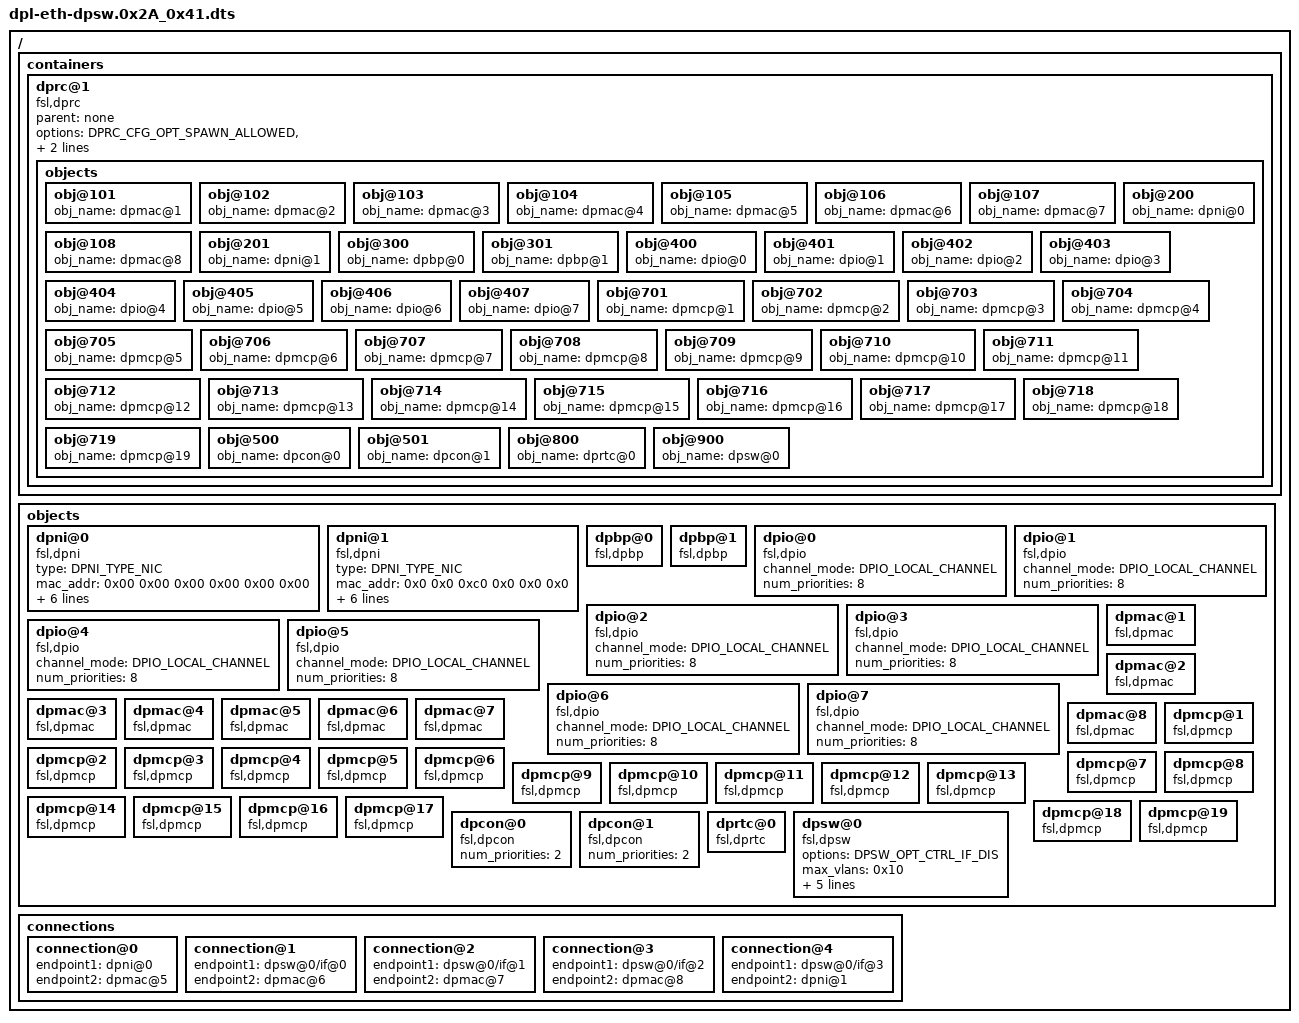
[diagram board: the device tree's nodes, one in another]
/*
 * Copyright 2014-2016 Freescale Semiconductor, Inc.
 * Copyright 2017 NXP
 *
 * Redistribution and use in source and binary forms, with or without
 * modification, are permitted provided that the following conditions are met:
 *   * Redistributions of source code must retain the above copyright
 *     notice, this list of conditions and the following disclaimer.
 *   * Redistributions in binary form must reproduce the above copyright
 *     notice, this list of conditions and the following disclaimer in the
 *     documentation and/or other materials provided with the distribution.
 *   * Neither the name of the above-listed copyright holders nor the
 *     names of any contributors may be used to endorse or promote products
 *     derived from this software without specific prior written permission.
 *
 * THIS SOFTWARE IS PROVIDED BY THE COPYRIGHT HOLDERS AND CONTRIBUTORS "AS IS"
 * AND ANY EXPRESS OR IMPLIED WARRANTIES, INCLUDING, BUT NOT LIMITED TO, THE
 * IMPLIED WARRANTIES OF MERCHANTABILITY AND FITNESS FOR A PARTICULAR PURPOSE
 * ARE DISCLAIMED. IN NO EVENT SHALL THE COPYRIGHT HOLDERS OR CONTRIBUTORS BE
 * LIABLE FOR ANY DIRECT, INDIRECT, INCIDENTAL, SPECIAL, EXEMPLARY, OR
 * CONSEQUENTIAL DAMAGES (INCLUDING, BUT NOT LIMITED TO, PROCUREMENT OF
 * SUBSTITUTE GOODS OR SERVICES; LOSS OF USE, DATA, OR PROFITS; OR BUSINESS
 * INTERRUPTION) HOWEVER CAUSED AND ON ANY THEORY OF LIABILITY, WHETHER IN
 * CONTRACT, STRICT LIABILITY, OR TORT (INCLUDING NEGLIGENCE OR OTHERWISE)
 * ARISING IN ANY WAY OUT OF THE USE OF THIS SOFTWARE, EVEN IF ADVISED OF THE
 * POSSIBILITY OF SUCH DAMAGE.
 */

/*
 * "Bootstrap DPL" for ls2088a RDB boards featuring SerDes 0x2A_0x41.
 * This DPL defines one network interface mapped on the ETH0 copper port and an
 * L2 switch, ports connected to internal interface ni1 and copper ports ETH1, ETH2
 * and ETH3.
 */
/dts-v1/;
/ {
	/*****************************************************************
         * Containers
         *****************************************************************/
	containers {
		dprc@1 {
			compatible = "fsl,dprc";
			parent = "none";
			options = "DPRC_CFG_OPT_SPAWN_ALLOWED" , "DPRC_CFG_OPT_ALLOC_ALLOWED", "DPRC_CFG_OPT_IRQ_CFG_ALLOWED";
			objects {
				/* ------------- MACs --------------*/
				obj@101 {
					obj_name = "dpmac@1";
				};
				obj@102 {
					obj_name = "dpmac@2";
				};
				obj@103 {
					obj_name = "dpmac@3";
				};
				obj@104 {
					obj_name = "dpmac@4";
				};
				obj@105 {
					obj_name = "dpmac@5";
				};
				obj@106 {
					obj_name = "dpmac@6";
				};
				obj@107 {
					obj_name = "dpmac@7";
				};
				obj@108 {
					obj_name = "dpmac@8";
				};

				/* ------------ DPNIs --------------*/
				obj@200 {
					obj_name = "dpni@0";
				};
				obj@201 {
					obj_name = "dpni@1";
				};

				/* ------------ DPBPs --------------*/
				obj@300 {
					obj_name = "dpbp@0";
				};
				obj@301 {
					obj_name = "dpbp@1";
				};

				/* ------------ DPIOs --------------*/
				obj@400 {
					obj_name = "dpio@0";
				};
				obj@401 {
					obj_name = "dpio@1";
				};
				obj@402 {
					obj_name = "dpio@2";
				};
				obj@403 {
					obj_name = "dpio@3";
				};
				obj@404 {
					obj_name = "dpio@4";
				};
				obj@405 {
					obj_name = "dpio@5";
				};
				obj@406 {
					obj_name = "dpio@6";
				};
				obj@407 {
					obj_name = "dpio@7";
				};

				/* ------------ DPMCPs --------------*/
				obj@701 {
					obj_name = "dpmcp@1";
				};
				obj@702 {
					obj_name = "dpmcp@2";
				};
				obj@703 {
					obj_name = "dpmcp@3";
				};
				obj@704 {
					obj_name = "dpmcp@4";
				};
				obj@705 {
					obj_name = "dpmcp@5";
				};
				obj@706 {
					obj_name = "dpmcp@6";
				};
				obj@707 {
					obj_name = "dpmcp@7";
				};
				obj@708 {
					obj_name = "dpmcp@8";
				};
				obj@709 {
					obj_name = "dpmcp@9";
				};
				obj@710 {
					obj_name = "dpmcp@10";
				};
				obj@711 {
					obj_name = "dpmcp@11";
				};
				obj@712 {
					obj_name = "dpmcp@12";
				};
				obj@713 {
					obj_name = "dpmcp@13";
				};
				obj@714 {
					obj_name = "dpmcp@14";
				};
				obj@715 {
					obj_name = "dpmcp@15";
				};
				obj@716 {
					obj_name = "dpmcp@16";
				};
				obj@717 {
					obj_name = "dpmcp@17";
				};
				obj@718 {
					obj_name = "dpmcp@18";
				};
				obj@719 {
					obj_name = "dpmcp@19";
				};

				/* ------------ DPCON --------------*/
				obj@500 {
					obj_name = "dpcon@0";
				};
				obj@501 {
					obj_name = "dpcon@1";
				};

				/* ------------ DPRTC --------------*/
				obj@800 {
					obj_name = "dprtc@0";
				};

				/* ------------ DPSW ---------------*/
				obj@900 {
					obj_name = "dpsw@0";
				};
			};
		};
	};

	/*****************************************************************
         * Objects
         *****************************************************************/
	objects {

		/* ------------ DPNI --------------*/
		dpni@0 {
			compatible = "fsl,dpni";
			type = "DPNI_TYPE_NIC";
			mac_addr = <0x00 0x00 0x00 0x00 0x00 0x00>;
			max_senders = <1>;
			options = "DPNI_OPT_MULTICAST_FILTER", "DPNI_OPT_UNICAST_FILTER";
			max_tcs = <1>;
			max_dist_per_tc = <1>;
			max_dist_key_size = <24>;
		};

		dpni@1 {
			compatible = "fsl,dpni";
			type = "DPNI_TYPE_NIC";
			mac_addr = <0x0 0x0 0xc0 0x0 0x0 0x0>;
			max_senders = <1>;
			options = "DPNI_OPT_MULTICAST_FILTER", "DPNI_OPT_UNICAST_FILTER";
			max_tcs = <1>;
			max_dist_per_tc = <1>;
			max_dist_key_size = <24>;
		};


		/* ------------ DPBP --------------*/
		dpbp@0 {
			compatible = "fsl,dpbp";
		};

		dpbp@1 {
			compatible = "fsl,dpbp";
		};

		/* ------------ DPIO --------------*/
		dpio@0 {
			compatible = "fsl,dpio";
			channel_mode = "DPIO_LOCAL_CHANNEL";
			num_priorities = <8>;
		};
		dpio@1 {
			compatible = "fsl,dpio";
			channel_mode = "DPIO_LOCAL_CHANNEL";
			num_priorities = <8>;
		};
		dpio@2 {
			compatible = "fsl,dpio";
			channel_mode = "DPIO_LOCAL_CHANNEL";
			num_priorities = <8>;
		};
		dpio@3 {
			compatible = "fsl,dpio";
			channel_mode = "DPIO_LOCAL_CHANNEL";
			num_priorities = <8>;
		};
		dpio@4 {
			compatible = "fsl,dpio";
			channel_mode = "DPIO_LOCAL_CHANNEL";
			num_priorities = <8>;
		};
		dpio@5 {
			compatible = "fsl,dpio";
			channel_mode = "DPIO_LOCAL_CHANNEL";
			num_priorities = <8>;
		};
		dpio@6 {
			compatible = "fsl,dpio";
			channel_mode = "DPIO_LOCAL_CHANNEL";
			num_priorities = <8>;
		};
		dpio@7 {
			compatible = "fsl,dpio";
			channel_mode = "DPIO_LOCAL_CHANNEL";
			num_priorities = <8>;
		};

		/* ------------ DPMAC --------------*/
		/* For SerDes 0x2A_0x41, DPMACs 1-4 are mapped to the optical
		 * PHYs while DPMACs 5-8 are mapped to the Cu PHYs.
		 * Object IDs are relevant, as the MC firmware currently uses
		 * them to identify the DPMACs directly, so dpmac@X is actually
		 * DPMAC#X.
		 */
		dpmac@1 {
			compatible = "fsl,dpmac";
		};
		dpmac@2 {
			compatible = "fsl,dpmac";
		};
		dpmac@3 {
			compatible = "fsl,dpmac";
		};
		dpmac@4 {
			compatible = "fsl,dpmac";
		};
		dpmac@5 {
			compatible = "fsl,dpmac";
		};
		dpmac@6 {
			compatible = "fsl,dpmac";
		};
		dpmac@7 {
			compatible = "fsl,dpmac";
		};
		dpmac@8 {
			compatible = "fsl,dpmac";
		};

		/* ------------ DPMCP --------------*/
		dpmcp@1 {
			compatible = "fsl,dpmcp";
		};
		dpmcp@2 {
			compatible = "fsl,dpmcp";
		};
		dpmcp@3 {
			compatible = "fsl,dpmcp";
		};
		dpmcp@4 {
			compatible = "fsl,dpmcp";
		};
		dpmcp@5 {
			compatible = "fsl,dpmcp";
		};
		dpmcp@6 {
			compatible = "fsl,dpmcp";
		};
		dpmcp@7 {
			compatible = "fsl,dpmcp";
		};
		dpmcp@8 {
			compatible = "fsl,dpmcp";
		};
		dpmcp@9 {
			compatible = "fsl,dpmcp";
		};
		dpmcp@10 {
			compatible = "fsl,dpmcp";
		};
		dpmcp@11 {
			compatible = "fsl,dpmcp";
		};
		dpmcp@12 {
			compatible = "fsl,dpmcp";
		};
		dpmcp@13 {
			compatible = "fsl,dpmcp";
		};
		dpmcp@14 {
			compatible = "fsl,dpmcp";
		};
		dpmcp@15 {
			compatible = "fsl,dpmcp";
		};
		dpmcp@16 {
			compatible = "fsl,dpmcp";
		};
		dpmcp@17 {
			compatible = "fsl,dpmcp";
		};
		dpmcp@18 {
			compatible = "fsl,dpmcp";
		};
		dpmcp@19 {
			compatible = "fsl,dpmcp";
		};

		/* ------------ DPCON --------------*/
		dpcon@0 {
			compatible = "fsl,dpcon";
			num_priorities = <2>;
		};

		dpcon@1 {
			compatible = "fsl,dpcon";
			num_priorities = <2>;
		};

		/* ------------ DPRTC --------------*/
		dprtc@0 {
			compatible = "fsl,dprtc";
		};

		/* ------------ DPSW ---------------*/
		dpsw@0 {
			compatible = "fsl,dpsw";
			options = "DPSW_OPT_CTRL_IF_DIS";
			max_vlans = <0x10>;
			max_fdbs = <0x1>;
			num_fdb_entries = <0x400>;
			fdb_aging_time = <0x12c>;
			num_ifs = <0x4>;
			max_fdb_mc_groups = <0x40>;
		};
	};

	/*****************************************************************
         * Connections
         *****************************************************************/
	connections {
		connection@0{
			/* Copper port (ETH0 on the RDB chassis) */
			endpoint1 = "dpni@0";
			endpoint2 = "dpmac@5";
		};

		connection@1 {
			/* Copper port (ETH1 on the RDB chassis) */
			endpoint1 = "dpsw@0/if@0";
			endpoint2 = "dpmac@6";
		};

		connection@2 {
			/* Copper port (ETH2 on the RDB chassis) */
			endpoint1 = "dpsw@0/if@1";
			endpoint2 = "dpmac@7";
		};

		connection@3 {
			/* Copper port (ETH3 on the RDB chassis) */
			endpoint1 = "dpsw@0/if@2";
			endpoint2 = "dpmac@8";
		};

		connection@4 {
			/* Internal port (ni1 in Linux) */
			endpoint1 = "dpsw@0/if@3";
			endpoint2 = "dpni@1";
		};
	};
};
